# DA14586 register map
Vendor: Dialog; Series: DA1458x; File version: 1.2
CPU: CM0 r1p0, little endian, MPU, FPU, 3 interrupt priority bits
Registers are 16-bit, read-write, reset 0x0 unless marked. A register's access mark holds for its fields unless they carry their own. Offsets are from the block's base; [hi:lo] are bit positions; {n}, {i} and the like mark numbered series; <NAME> marks a mode.

## riscutil580_wdog_nl00 — riscutil580_wdog_nl00 registers
Base 0x50003100
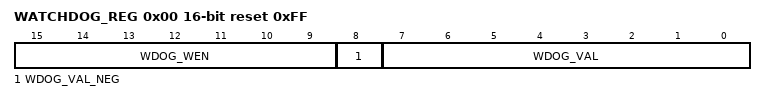
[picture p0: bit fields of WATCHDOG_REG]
0x00 WATCHDOG_REG reset 0xFF — Watchdog timer register.
  [15:9] WDOG_WEN wo — 0000.000 = Write enable for Watchdog timer else Write disable. This filter prevents unintentional presetting the watchdog with a SW run-away.
  [8] WDOG_VAL_NEG — 0 = Watchdog timer value is positive. 1 = Watchdog timer value is negative.
  [7:0] WDOG_VAL — Write: Watchdog timer reload value. Note that all bits 15-9 must be 0 to reload this register. Read: Actual Watchdog timer value. Decremented by 1 every 10.24 msec. Bit 8 indicates a negative counter value. 2, 1, 0, 1FF16, 1FE16 etc. An NMI or WDOG (SYS) reset is generated under the following conditions: If WATCHDOG_CTRL_REG[NMI_RST] = 0 then If WDOG_VAL = 0 -> NMI (Non Maskable Interrupt) if WDOG_VAL = 1F016 -> WDOG reset -> reload FF16 If WATCHDOG_CTRL_REG[NMI_RST] = 1 then if WDOG_VAL <= 0 -> WDOG reset -> reload FF16
0x02 WATCHDOG_CTRL_REG — Watchdog control register.
  [0] NMI_RST — 0 = Watchdog timer generates NMI at value 0, and WDOG (SYS) reset at <=-16. Timer can be frozen /resumed using SET_FREEZE_REG[FRZ_WDOG]/ RESET_FREEZE_REG[FRZ_WDOG]. 1 = Watchdog timer generates a WDOG (SYS) reset at value 0 and can not be frozen by Software. Note that this bit can only be set to 1 by SW and only be reset with a WDOG (SYS) reset or SW reset. The watchdog is always frozen when the Cortex-M0 is halted in DEBUG State.

## tmr580_nl01 — tmr580_nl01 registers
Base 0x50003400
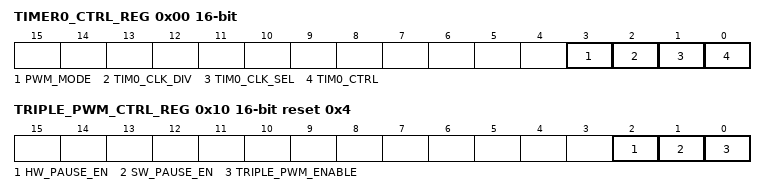
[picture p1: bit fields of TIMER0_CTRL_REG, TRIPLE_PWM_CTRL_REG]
0x00 TIMER0_CTRL_REG — Timer0 control register
  [3] PWM_MODE — 0 = PWM signals are '1' during high time. 1 = PWM signals send out the (fast) clock divided by 2 during high time. So it will be in the range of 1 to 8 MHz.
  [2] TIM0_CLK_DIV — 1 = Timer0 uses selected clock frequency as is. 0 = Timer0 uses selected clock frequency divided by 10. Note that this applies only to the ON-counter.
  [1] TIM0_CLK_SEL — 1 = Timer0 uses 16, 8, 4 or 2 MHz (fast) clock frequency. 0 = Timer0 uses 32 kHz (slow) clock frequency.
  [0] TIM0_CTRL — 0 = Timer0 is off and in reset state. 1 = Timer0 is running.
0x02 TIMER0_ON_REG — Timer0 on control register
  [15:0] TIM0_ON wo — Timer0 On reload value: If read the actual counter value ON_CNTer is returned
0x04 TIMER0_RELOAD_M_REG — 16 bits reload value for Timer0
  [15:0] TIM0_M wo — Timer0 'high' reload valueIf read the actual counter value T0_CNTer is returned
0x06 TIMER0_RELOAD_N_REG — 16 bits reload value for Timer0
  [15:0] TIM0_N wo — Timer0 'low' reload value: If read the actual counter value T0_CNTer is returned
{0x4+2i} PWM{i}_DUTY_CYCLE (i=2..4) — Duty Cycle for PWM{i}
  [13:0] DUTY_CYCLE — duty cycle for PWM
0x0E TRIPLE_PWM_FREQUENCY — Frequency for PWM 2,3 and 4
  [13:0] FREQ — Freq for PWM 2 3 4
0x10 TRIPLE_PWM_CTRL_REG reset 0x4 — PWM 2 3 4 Control
  [2] HW_PAUSE_EN — '1' = HW can pause PWM 2,3,4
  [1] SW_PAUSE_EN — '1' = PWM 2 3 4 is paused
  [0] TRIPLE_PWM_ENABLE — '1' = PWM 2 3 4 is enabled

## wkup580_nl01 — wkup580_nl01 registers
Base 0x50000100
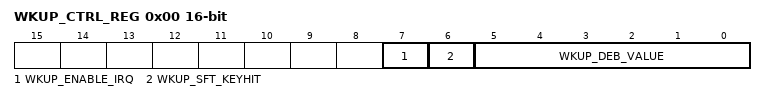
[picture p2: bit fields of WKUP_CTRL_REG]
0x00 WKUP_CTRL_REG — Control register for the wakeup counter
  [7] WKUP_ENABLE_IRQ — 0: no interrupt will be enabled 1: if the event counter reaches the value set by WKUP_COMPARE_REG an IRQ will be generated
  [6] WKUP_SFT_KEYHIT — 0: no effect 1: emulate key hit. The event counter will increment by 1 (after debouncing if enabled). First make this bit 0 before any new key hit can be sensed.
  [5:0] WKUP_DEB_VALUE — Keyboard debounce time (N*1 ms with N = 1 to 63). 0x0: no debouncing 0x1 to 0x3F: 1 ms to 63 ms debounce time
0x02 WKUP_COMPARE_REG — Number of events before wakeup interrupt
  [7:0] COMPARE — The number of events that have to be counted before the wakeup interrupt will be given
0x04 WKUP_RESET_IRQ_REG — Reset wakeup interrupt
  [15:0] WKUP_IRQ_RST wo — writing any value to this register will reset the interrupt. reading always returns 0.
0x06 WKUP_COUNTER_REG — Actual number of events of the wakeup counter
  [7:0] EVENT_VALUE ro — This value represents the number of events that have been counted so far. It will be reset by resetting the interrupt.
0x08 WKUP_RESET_CNTR_REG — Reset the event counter
  [15:0] WKUP_CNTR_RST wo — writing any value to this register will reset the event counter
0x0A WKUP_SELECT_P0_REG — Select which inputs from P0 port can trigger wkup counter
  [7:0] WKUP_SELECT_P0 — 0: input P0x is not enabled for wakeup event counter 1: input P0x is enabled for wakeup event counter
0x0C WKUP_SELECT_P1_REG — Select which inputs from P1 port can trigger wkup counter
  [5:0] WKUP_SELECT_P1 — 0: input P1x is not enabled for wakeup event counter 1: input P1x is enabled for wakeup event counter
0x0E WKUP_SELECT_P2_REG — Select which inputs from P2 port can trigger wkup counter
  [9:0] WKUP_SELECT_P2 — 0: input P2x is not enabled for wakeup event counter 1: input P2x is enabled for wakeup event counter
0x10 WKUP_SELECT_P3_REG — Select which inputs from P3 port can trigger wkup counter
  [7:0] WKUP_SELECT_P3 — 0: input P3x is not enabled for wakeup event counter 1: input P3x is enabled for wakeup event counter
0x12 WKUP_POL_P0_REG — Select the sensitivity polarity for each P0 input
  [7:0] WKUP_POL_P0 — 0: enabled input P0x will increment the event counter if that input goes high 1: enabled input P0x will increment the event counter if that input goes low
0x14 WKUP_POL_P1_REG — Select the sensitivity polarity for each P1 input
  [5:0] WKUP_POL_P1 — 0: enabled input P1x will increment the event counter if that input goes high 1: enabled input P1x will increment the event counter if that input goes low
0x16 WKUP_POL_P2_REG — Select the sensitivity polarity for each P2 input
  [9:0] WKUP_POL_P2 — 0: enabled input P2x will increment the event counter if that input goes high 1: enabled input P2x will increment the event counter if that input goes low
0x18 WKUP_POL_P3_REG — Select the sensitivity polarity for each P3 input
  [7:0] WKUP_POL_P3 — 0: enabled input P3x will increment the event counter if that input goes high 1: enabled input P3x will increment the event counter if that input goes low
